# AT32F403xx_v2 register map
Vendor: Keil; Series: AT32F403; File version: 1.0
CPU: CM4 r0p1, little endian, no MPU, FPU, 4 interrupt priority bits
Registers are 32-bit, read-write, reset 0x0 unless marked. A register's access mark holds for its fields unless they carry their own. Offsets are from the block's base; [hi:lo] are bit positions; {n}, {i} and the like mark numbered series; 'fields as' and 'values as' point back to an identical list.

## XMC — Flexible static memory controller
Base 0xA0000000
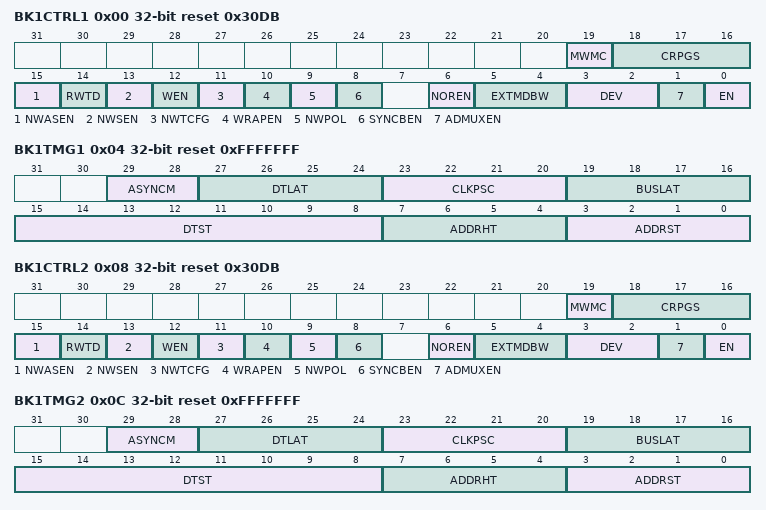
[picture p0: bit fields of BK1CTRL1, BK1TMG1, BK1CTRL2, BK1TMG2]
0x00 BK1CTRL1 reset 0x30DB — SRAM/NOR-Flash chip-select control register 1
  [19] MWMC — Memory write mode control
  [18:16] CRPGS — CRAM page size
  [15] NWASEN — NWAIT in asynchronous transfer enable
  [14] RWTD — Read-write timing different
  [13] NWSEN — NWAIT in synchronous transfer enable
  [12] WEN — Write enable
  [11] NWTCFG — Wait timing configuration
  [10] WRAPEN — Wrapped enable
  [9] NWPOL — NWAIT polarity
  [8] SYNCBEN — Synchronous burst enable
  [6] NOREN — Nor flash access enable
  [5:4] EXTMDBW — External memory data bus width
  [3:2] DEV — Memory device type
  [1] ADMUXEN — Address and data multiplexing enable
  [0] EN — Memory bank enable
0x04 BK1TMG1 reset 0xFFFFFFF — SRAM/NOR-Flash chip-select timing register 1
  [29:28] ASYNCM — Asynchronous mode
  [27:24] DTLAT — Data latency
  [23:20] CLKPSC — Clock prescale
  [19:16] BUSLAT — Bus latency
  [15:8] DTST — Asynchronous data setup time
  [7:4] ADDRHT — Address-hold time
  [3:0] ADDRST — Address setup time
0x08 BK1CTRL2 reset 0x30DB — SRAM/NOR-Flash chip-select control register 2
  fields as BK1CTRL1
0x0C BK1TMG2 reset 0xFFFFFFF — SRAM/NOR-Flash chip-select timing register 2
  fields as BK1TMG1
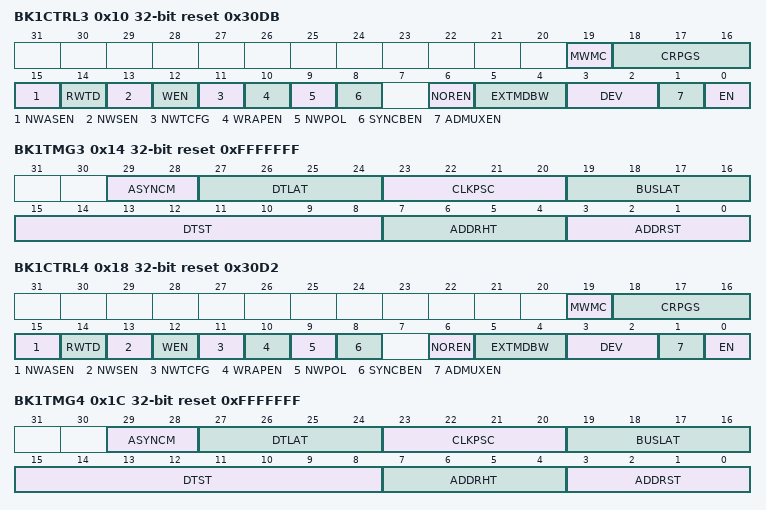
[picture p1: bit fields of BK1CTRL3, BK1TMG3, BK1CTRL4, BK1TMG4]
0x10 BK1CTRL3 reset 0x30DB — SRAM/NOR-Flash chip-select control register 3
  fields as BK1CTRL1
0x14 BK1TMG3 reset 0xFFFFFFF — SRAM/NOR-Flash chip-select timing register 3
  fields as BK1TMG1
0x18 BK1CTRL4 reset 0x30D2 — SRAM/NOR-Flash chip-select control register 4
  fields as BK1CTRL1
0x1C BK1TMG4 reset 0xFFFFFFF — SRAM/NOR-Flash chip-select timing register 4
  fields as BK1TMG1
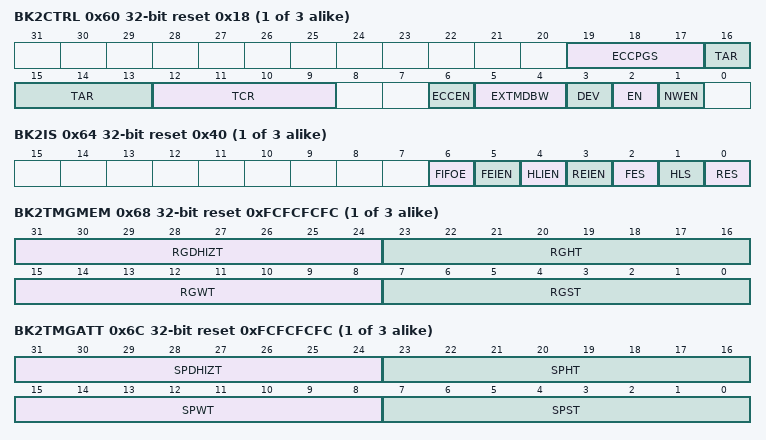
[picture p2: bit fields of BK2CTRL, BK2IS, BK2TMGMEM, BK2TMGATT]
{0x20+0x20*i} BK{i}CTRL reset 0x18 (i=2..4) — PC Card/NAND Flash control register {i}
  [19:17] ECCPGS — ECC page size
  [16:13] TAR — ALE to RE delay
  [12:9] TCR — CLE to RE delay
  [6] ECCEN — ECC enable
  [5:4] EXTMDBW — External memory data bus width
  [3] DEV — Memory device type
  [2] EN — Memory bank enable
  [1] NWEN — Wait feature enable
{0x24+0x20*i} BK{i}IS reset 0x40 (i=2..4) — FIFO status and interrupt register {i}
  [6] FIFOE ro — FIFO empty
  [5] FEIEN — Falling edge interrupt enable
  [4] HLIEN — High-level interrupt enable
  [3] REIEN — Rising edge interrupt enable
  [2] FES — Falling edge status
  [1] HLS — High-level status
  [0] RES — Rising edge capture status
{0x28+0x20*i} BK{i}TMGMEM reset 0xFCFCFCFC (i=2..4) — Regular memory space timing register {i}
  [31:24] RGDHIZT — Regular memory databus High resistance time
  [23:16] RGHT — Regular memory hold time
  [15:8] RGWT — Regular memory wait time
  [7:0] RGST — Regular memory setup time
{0x2C+0x20*i} BK{i}TMGATT reset 0xFCFCFCFC (i=2..4) — special memory space timing register {i}
  [31:24] SPDHIZT — special memory databus High resistance time
  [23:16] SPHT — special memory hold time
  [15:8] SPWT — special memory wait time
  [7:0] SPST — special memory setup time
0x74 BK2ECC — ECC result register 2
  [31:0] ECC — ECC result
0x94 BK3ECC — ECC result register 3
  [31:0] ECC — ECC result
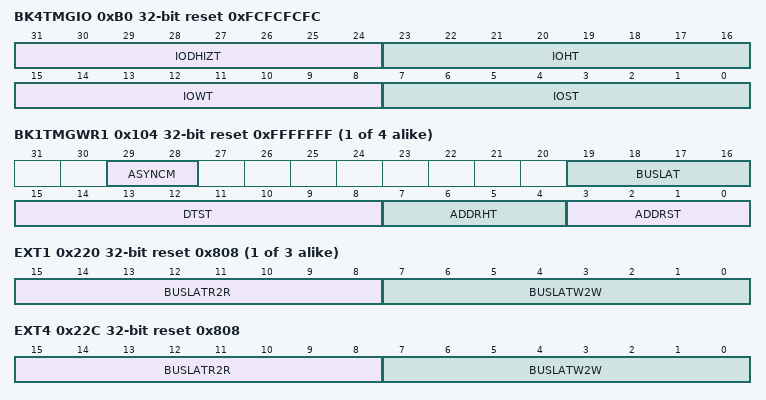
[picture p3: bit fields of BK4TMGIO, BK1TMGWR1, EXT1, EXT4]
0xB0 BK4TMGIO reset 0xFCFCFCFC — special IO space timing register 4
  [31:24] IODHIZT — IO space databus High resistance time
  [23:16] IOHT — IO space hold time
  [15:8] IOWT — IO space wait time
  [7:0] IOST — IO space setup time
{0xFC+8i} BK1TMGWR{i} reset 0xFFFFFFF (i=1..4) — SRAM/NOR-Flash write timing registers {i}
  [29:28] ASYNCM — Asynchronous mode
  [19:16] BUSLAT — Bus latency
  [15:8] DTST — Asynchronous data setup time
  [7:4] ADDRHT — Address-hold time
  [3:0] ADDRST — Address setup time
{0x21C+4i} EXT{i} reset 0x808 (i=1..3) — externl timeing register {i}
  [15:8] BUSLATR2R — Bus turnaround phase for consecutive read duration
  [7:0] BUSLATW2W — Bus turnaround phase for consecutive write duration
0x22C EXT4 reset 0x808 — externl timeing register 4
  [15:8] BUSLATR2R, [7:0] BUSLATW2W

## Notices in the file
Copyright (C) 2012-2014 ARM Limited. All rights reserved.
Purpose: System Viewer Description (SVD) Example (Schema Version 1.1)
This is a description of a none-existent and incomplete device
for demonstration purposes only.
Redistribution and use in source and binary forms, with or without
modification, are permitted provided that the following conditions are met:
- Redistributions of source code must retain the above copyright
notice, this list of conditions and the following disclaimer.
- Redistributions in binary form must reproduce the above copyright
notice, this list of conditions and the following disclaimer in the
documentation and/or other materials provided with the distribution.
- Neither the name of ARM nor the names of its contributors may be used
to endorse or promote products derived from this software without
specific prior written permission.
THIS SOFTWARE IS PROVIDED BY THE COPYRIGHT HOLDERS AND CONTRIBUTORS "AS IS"
AND ANY EXPRESS OR IMPLIED WARRANTIES, INCLUDING, BUT NOT LIMITED TO, THE
IMPLIED WARRANTIES OF MERCHANTABILITY AND FITNESS FOR A PARTICULAR PURPOSE
ARE DISCLAIMED. IN NO EVENT SHALL COPYRIGHT HOLDERS AND CONTRIBUTORS BE
LIABLE FOR ANY DIRECT, INDIRECT, INCIDENTAL, SPECIAL, EXEMPLARY, OR
CONSEQUENTIAL DAMAGES (INCLUDING, BUT NOT LIMITED TO, PROCUREMENT OF
SUBSTITUTE GOODS OR SERVICES; LOSS OF USE, DATA, OR PROFITS; OR BUSINESS
INTERRUPTION) HOWEVER CAUSED AND ON ANY THEORY OF LIABILITY, WHETHER IN
CONTRACT, STRICT LIABILITY, OR TORT (INCLUDING NEGLIGENCE OR OTHERWISE)
ARISING IN ANY WAY OUT OF THE USE OF THIS SOFTWARE, EVEN IF ADVISED OF THE
POSSIBILITY OF SUCH DAMAGE.
